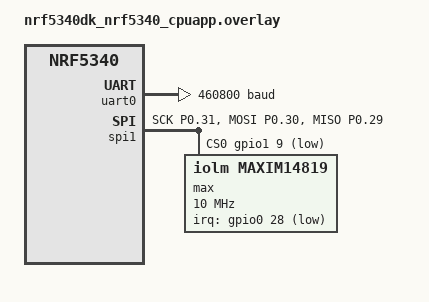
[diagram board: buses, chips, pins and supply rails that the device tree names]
&uart0 {
	status = "okay";
	current-speed = <460800>;
};

&pinctrl {

	spi1_default_alt: spi1_default_alt {
		group1 {
			psels = <NRF_PSEL(SPIM_SCK, 0, 31)>,
				<NRF_PSEL(SPIM_MOSI, 0, 30)>,
				<NRF_PSEL(SPIM_MISO, 0,29)>;
		};
	};

	spi1_sleep_alt: spi1_sleep_alt {
		group1 {
			psels = <NRF_PSEL(SPIM_SCK, 0, 31)>,
				<NRF_PSEL(SPIM_MOSI, 0, 30)>,
				<NRF_PSEL(SPIM_MISO, 0, 29)>;
			low-power-enable;
		};
	};

};

//#include <iolm/maxim14819.h>

&spi1 {
	status = "okay";
	compatible = "nordic,nrf-spim";
	pinctrl-0 = <&spi1_default_alt>;
	pinctrl-1 = <&spi1_sleep_alt>;
	pinctrl-names = "default", "sleep";
	cs-gpios = <&gpio1 9 GPIO_ACTIVE_LOW>;
    max:maxim14819@0 {
		spi-max-frequency = <10000000>;
		status = "okay";
		irq-gpios = <&gpio0 28 GPIO_ACTIVE_LOW>;
        compatible = "iolm,maxim14819";
        reg = <0x00>;
		chip-address = <0x00>;
    };
};
